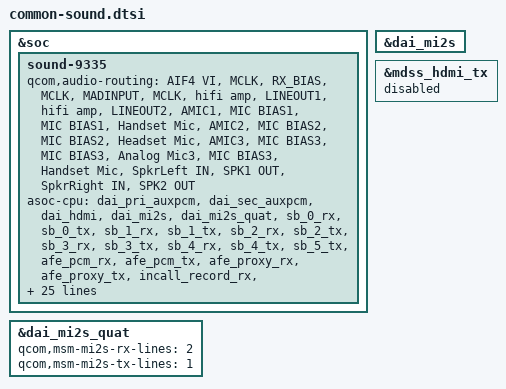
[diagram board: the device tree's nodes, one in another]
&soc {
	sound-9335 {
		qcom,audio-routing = 
			"AIF4 VI", "MCLK", 
			"RX_BIAS", "MCLK", 
			"MADINPUT", "MCLK", 
			"hifi amp", "LINEOUT1", 
			"hifi amp", "LINEOUT2", 
			"AMIC1", "MIC BIAS1", 
			"MIC BIAS1", "Handset Mic", 
			"AMIC2", "MIC BIAS2", 
			"MIC BIAS2", "Headset Mic", 
			"AMIC3", "MIC BIAS3", 
			"MIC BIAS3", "Analog Mic3", 
			"MIC BIAS3", "Handset Mic", 
			"SpkrLeft IN", "SPK1 OUT",
			"SpkrRight IN", "SPK2 OUT";
		asoc-cpu = <&dai_pri_auxpcm>, <&dai_sec_auxpcm>, <&dai_hdmi>, <&dai_mi2s>, <&dai_mi2s_quat>,
				<&sb_0_rx>, <&sb_0_tx>, <&sb_1_rx>, <&sb_1_tx>,
				<&sb_2_rx>, <&sb_2_tx>, <&sb_3_rx>, <&sb_3_tx>,
				<&sb_4_rx>, <&sb_4_tx>, <&sb_5_tx>, <&afe_pcm_rx>,
				<&afe_pcm_tx>, <&afe_proxy_rx>, <&afe_proxy_tx>,
				<&incall_record_rx>, <&incall_record_tx>,
				<&incall_music_rx>, <&incall_music2_rx>,
				<&sb_5_rx>, <&sb_6_rx>;
		asoc-cpu-names = "msm-dai-q6-auxpcm.1", "msm-dai-q6-auxpcm.2",
				"msm-dai-q6-hdmi.8", "msm-dai-q6-mi2s.2","msm-dai-q6-mi2s.3",
				"msm-dai-q6-dev.16384", "msm-dai-q6-dev.16385",
				"msm-dai-q6-dev.16386", "msm-dai-q6-dev.16387",
				"msm-dai-q6-dev.16388", "msm-dai-q6-dev.16389",
				"msm-dai-q6-dev.16390", "msm-dai-q6-dev.16391",
				"msm-dai-q6-dev.16392", "msm-dai-q6-dev.16393",
				"msm-dai-q6-dev.16395", "msm-dai-q6-dev.224",
				"msm-dai-q6-dev.225", "msm-dai-q6-dev.241",
				"msm-dai-q6-dev.240", "msm-dai-q6-dev.32771",
				"msm-dai-q6-dev.32772", "msm-dai-q6-dev.32773",
				"msm-dai-q6-dev.32770", "msm-dai-q6-dev.16394",
				"msm-dai-q6-dev.16396";
		/delete-property/ qcom,hdmi-audio-rx;
		asoc-codec = <&stub_codec>;
		asoc-codec-names = "msm-stub-codec.1";
		qcom,msm-mbhc-hphl-swh = <1>;
		qcom,msm-mbhc-gnd-swh = <1>;
		qcom,mbhc-audio-jack-type = "4-pole-jack";
		ncx_vdd-supply = <&pm8994_l19>;
		qcom,wsa-max-devs = <1>;
		qcom,wsa-devs =  <&wsa881x_213>;
		qcom,wsa-aux-dev-prefix = "SpkrLeft";
	};
};

&dai_mi2s {
	/delete-property/ pinctrl-0;
	/delete-property/ pinctrl-1;
};

&dai_mi2s_quat {
	qcom,msm-mi2s-rx-lines = <2>;
	qcom,msm-mi2s-tx-lines = <1>;
};

&mdss_hdmi_tx {
	status = "disabled";
};
